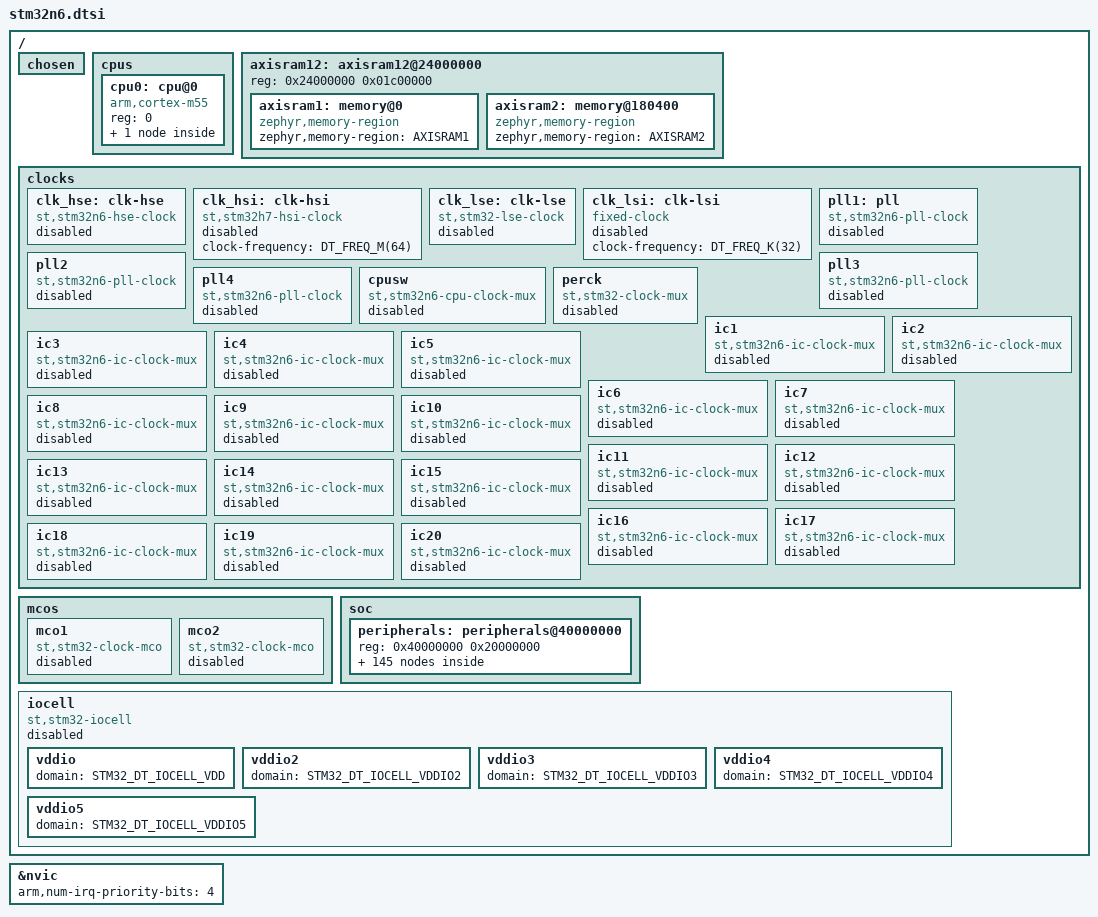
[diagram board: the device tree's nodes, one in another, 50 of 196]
/*
 * Copyright (c) 2024 STMicroelectronics
 * Copyright (c) 2025 Mario Paja
 *
 * SPDX-License-Identifier: Apache-2.0
 */

#include <arm/armv8.1-m.dtsi>
#include <zephyr/dt-bindings/adc/adc.h>
#include <zephyr/dt-bindings/clock/stm32n6_clock.h>
#include <zephyr/dt-bindings/dma/stm32_dma.h>
#include <zephyr/dt-bindings/i2c/i2c.h>
#include <zephyr/dt-bindings/reset/stm32n6_reset.h>
#include <zephyr/dt-bindings/memory-attr/memory-attr.h>
#include <zephyr/dt-bindings/memory-attr/memory-attr-arm.h>
#include <zephyr/dt-bindings/memory-controller/stm32-fmc-nor-psram.h>
#include <zephyr/dt-bindings/gpio/gpio.h>
#include <zephyr/dt-bindings/video/video-interfaces.h>
#include <zephyr/dt-bindings/power/stm32n6_iocell.h>
#include <freq.h>
#include <mem.h>

/ {
	chosen {
		zephyr,crc = &crc;
		zephyr,entropy = &rng;
	};

	cpus {
		#address-cells = <1>;
		#size-cells = <0>;

		cpu0: cpu@0 {
			device_type = "cpu";
			compatible = "arm,cortex-m55";
			reg = <0>;
			#address-cells = <1>;
			#size-cells = <1>;

			mpu: mpu@e000ed90 {
				compatible = "arm,armv8.1m-mpu";
				reg = <0xe000ed90 0x40>;
			};
		};
	};

	axisram12: axisram12@24000000 {
		#address-cells = <1>;
		#size-cells = <1>;
		/* This node described FLEXMEM, AXISRAM1 and AXISRAM2 */
		reg = <0x24000000 0x01c00000>;
		ranges = <0x0 0x34000000 DT_SIZE_M(2)>;

		axisram1: memory@0 {
			compatible = "zephyr,memory-region", "mmio-sram";
			zephyr,memory-region = "AXISRAM1";
		};

		axisram2: memory@180400 {
			compatible = "zephyr,memory-region", "mmio-sram";
			zephyr,memory-region = "AXISRAM2";
		};
	};

	clocks {
		clk_hse: clk-hse {
			#clock-cells = <0>;
			compatible = "st,stm32n6-hse-clock";
			status = "disabled";
		};

		clk_hsi: clk-hsi {
			#clock-cells = <0>;
			compatible = "st,stm32h7-hsi-clock";
			clock-frequency = <DT_FREQ_M(64)>;
			status = "disabled";
		};

		clk_lse: clk-lse {
			#clock-cells = <0>;
			compatible = "st,stm32-lse-clock";
			clock-frequency = <32768>;
			driving-capability = <2>;
			status = "disabled";
		};

		clk_lsi: clk-lsi {
			#clock-cells = <0>;
			compatible = "fixed-clock";
			clock-frequency = <DT_FREQ_K(32)>;
			status = "disabled";
		};

		pll1: pll: pll {
			#clock-cells = <0>;
			compatible = "st,stm32n6-pll-clock";
			status = "disabled";
		};

		pll2: pll2 {
			#clock-cells = <0>;
			compatible = "st,stm32n6-pll-clock";
			status = "disabled";
		};

		pll3: pll3 {
			#clock-cells = <0>;
			compatible = "st,stm32n6-pll-clock";
			status = "disabled";
		};

		pll4: pll4 {
			#clock-cells = <0>;
			compatible = "st,stm32n6-pll-clock";
			status = "disabled";
		};

		cpusw: cpusw {
			#clock-cells = <0>;
			compatible = "st,stm32n6-cpu-clock-mux", "st,stm32-clock-mux";
			status = "disabled";
		};

		perck: perck {
			#clock-cells = <0>;
			compatible = "st,stm32-clock-mux";
			status = "disabled";
		};

		ic1: ic1 {
			#clock-cells = <0>;
			compatible = "st,stm32n6-ic-clock-mux";
			status = "disabled";
		};

		ic2: ic2 {
			#clock-cells = <0>;
			compatible = "st,stm32n6-ic-clock-mux";
			status = "disabled";
		};

		ic3: ic3 {
			#clock-cells = <0>;
			compatible = "st,stm32n6-ic-clock-mux";
			status = "disabled";
		};

		ic4: ic4 {
			#clock-cells = <0>;
			compatible = "st,stm32n6-ic-clock-mux";
			status = "disabled";
		};

		ic5: ic5 {
			#clock-cells = <0>;
			compatible = "st,stm32n6-ic-clock-mux";
			status = "disabled";
		};

		ic6: ic6 {
			#clock-cells = <0>;
			compatible = "st,stm32n6-ic-clock-mux";
			status = "disabled";
		};

		ic7: ic7 {
			#clock-cells = <0>;
			compatible = "st,stm32n6-ic-clock-mux";
			status = "disabled";
		};

		ic8: ic8 {
			#clock-cells = <0>;
			compatible = "st,stm32n6-ic-clock-mux";
			status = "disabled";
		};

		ic9: ic9 {
			#clock-cells = <0>;
			compatible = "st,stm32n6-ic-clock-mux";
			status = "disabled";
		};

		ic10: ic10 {
			#clock-cells = <0>;
			compatible = "st,stm32n6-ic-clock-mux";
			status = "disabled";
		};

		ic11: ic11 {
			#clock-cells = <0>;
			compatible = "st,stm32n6-ic-clock-mux";
			status = "disabled";
		};

		ic12: ic12 {
			#clock-cells = <0>;
			compatible = "st,stm32n6-ic-clock-mux";
			status = "disabled";
		};

		ic13: ic13 {
			#clock-cells = <0>;
			compatible = "st,stm32n6-ic-clock-mux";
			status = "disabled";
		};

		ic14: ic14 {
			#clock-cells = <0>;
			compatible = "st,stm32n6-ic-clock-mux";
			status = "disabled";
		};

		ic15: ic15 {
			#clock-cells = <0>;
			compatible = "st,stm32n6-ic-clock-mux";
			status = "disabled";
		};

		ic16: ic16 {
			#clock-cells = <0>;
			compatible = "st,stm32n6-ic-clock-mux";
			status = "disabled";
		};

		ic17: ic17 {
			#clock-cells = <0>;
			compatible = "st,stm32n6-ic-clock-mux";
			status = "disabled";
		};

		ic18: ic18 {
			#clock-cells = <0>;
			compatible = "st,stm32n6-ic-clock-mux";
			status = "disabled";
		};

		ic19: ic19 {
			#clock-cells = <0>;
			compatible = "st,stm32n6-ic-clock-mux";
			status = "disabled";
		};

		ic20: ic20 {
			#clock-cells = <0>;
			compatible = "st,stm32n6-ic-clock-mux";
			status = "disabled";
		};
	};

	mcos {
		mco1: mco1 {
			#clock-cells = <2>;
			compatible = "st,stm32-clock-mco";
			clocks = <&rcc STM32_CLOCK(MISC, 1)>,
				 <&rcc STM32_SRC_HSI MCO1_SEL(MCO1_SEL_HSI)>;
			clock-names = "clken", "clksel";
			status = "disabled";
		};

		mco2: mco2 {
			#clock-cells = <2>;
			compatible = "st,stm32-clock-mco";
			clocks = <&rcc STM32_CLOCK(MISC, 2)>,
				 <&rcc STM32_SRC_HSI MCO2_SEL(MCO2_SEL_HSI)>;
			clock-names = "clken", "clksel";
			status = "disabled";
		};
	};

	soc {
		#address-cells = <1>;
		#size-cells = <1>;

		peripherals: peripherals@40000000 {
			#address-cells = <1>;
			#size-cells = <1>;
			reg = <0x40000000 0x20000000>;
			/* Default use the secure addresses range */
			ranges = <0x0 0x50000000 0x10000000>;

			rcc: rcc@6028000 {
				compatible = "st,stm32n6-rcc";
				clocks-controller;
				#clock-cells = <2>;
				reg = <0x6028000 0x2000>;

				rctl: reset-controller {
					compatible = "st,stm32-rcc-rctl";
					#reset-cells = <1>;
				};
			};

			ramcfg_sram3_axi: ramcfg@2023100 {
				compatible = "st,stm32n6-ramcfg";
				#address-cells = <1>;
				#size-cells = <1>;
				reg = <0x2023100 0x80>;
				clocks = <&rcc STM32_CLOCK(MEM, 0)>, <&rcc STM32_CLOCK(AHB2, 12)>;
				clock-names = "axisram", "ramcfg";
				ranges = <0x0 0x34200000 DT_SIZE_K(448)>;

				axisram3: memory@0 {
					compatible = "zephyr,memory-region", "mmio-sram";
					zephyr,memory-region = "AXISRAM3";
					zephyr,memory-attr = <DT_MEM_ARM(ATTR_MPU_RAM)>;
				};
			};

			ramcfg_sram4_axi: ramcfg@2023180 {
				compatible = "st,stm32n6-ramcfg";
				#address-cells = <1>;
				#size-cells = <1>;
				reg = <0x2023180 0x80>;
				clocks = <&rcc STM32_CLOCK(MEM, 1)>, <&rcc STM32_CLOCK(AHB2, 12)>;
				clock-names = "axisram", "ramcfg";
				ranges = <0x0 0x34270000 DT_SIZE_K(448)>;

				axisram4: memory@0 {
					compatible = "zephyr,memory-region", "mmio-sram";
					zephyr,memory-region = "AXISRAM4";
					zephyr,memory-attr = <DT_MEM_ARM(ATTR_MPU_RAM)>;
				};
			};

			ramcfg_sram5_axi: ramcfg@2023200 {
				compatible = "st,stm32n6-ramcfg";
				#address-cells = <1>;
				#size-cells = <1>;
				reg = <0x2023200 0x80>;
				clocks = <&rcc STM32_CLOCK(MEM, 2)>, <&rcc STM32_CLOCK(AHB2, 12)>;
				clock-names = "axisram", "ramcfg";
				ranges = <0x0 0x342e0000 DT_SIZE_K(448)>;

				axisram5: memory@0 {
					compatible = "zephyr,memory-region", "mmio-sram";
					zephyr,memory-region = "AXISRAM5";
					zephyr,memory-attr = <DT_MEM_ARM(ATTR_MPU_RAM)>;
				};
			};

			ramcfg_sram6_axi: ramcfg@2023280 {
				compatible = "st,stm32n6-ramcfg";
				#address-cells = <1>;
				#size-cells = <1>;
				reg = <0x2023280 0x80>;
				clocks = <&rcc STM32_CLOCK(MEM, 3)>, <&rcc STM32_CLOCK(AHB2, 12)>;
				clock-names = "axisram", "ramcfg";
				ranges = <0x0 0x34350000 DT_SIZE_K(448)>;

				axisram6: memory@0 {
					compatible = "zephyr,memory-region", "mmio-sram";
					zephyr,memory-region = "AXISRAM6";
					zephyr,memory-attr = <DT_MEM_ARM(ATTR_MPU_RAM)>;
				};
			};

			exti: interrupt-controller@6025000 {
				compatible = "st,stm32g0-exti", "st,stm32-exti";
				interrupt-controller;
				#interrupt-cells = <1>;
				#address-cells = <0>;
				reg = <0x6025000 0x400>;
				clocks = <&rcc STM32_CLOCK(APB4_2, 0)>;
				num-lines = <96>;
				interrupts = <20 0>, <21 0>, <22 0>, <23 0>,
					     <24 0>, <25 0>, <26 0>, <27 0>,
					     <28 0>, <29 0>, <30 0>, <31 0>,
					     <32 0>, <33 0>, <34 0>, <35 0>;
				interrupt-names = "line0", "line1", "line2", "line3",
						  "line4", "line5", "line6", "line7",
						  "line8", "line9", "line10", "line11",
						  "line12", "line13", "line14", "line15";
				line-ranges = <0 1>, <1 1>, <2 1>, <3 1>,
					      <4 1>, <5 1>, <6 1>, <7 1>,
					      <8 1>, <9 1>, <10 1>, <11 1>,
					      <12 1>, <13 1>, <14 1>, <15 1>;
			};

			pinctrl: pin-controller@6020000 {
				compatible = "st,stm32n6-pinctrl", "st,stm32-pinctrl";
				#address-cells = <1>;
				#size-cells = <1>;
				reg = <0x6020000 0x2000>;
				ranges;

				gpioa: gpio@6020000 {
					compatible = "st,stm32-gpio";
					gpio-controller;
					#gpio-cells = <2>;
					reg = <0x6020000 0x400>;
					clocks = <&rcc STM32_CLOCK(AHB4, 0)>;
				};

				gpiob: gpio@6020400 {
					compatible = "st,stm32-gpio";
					gpio-controller;
					#gpio-cells = <2>;
					reg = <0x6020400 0x400>;
					clocks = <&rcc STM32_CLOCK(AHB4, 1)>;
				};

				gpioc: gpio@6020800 {
					compatible = "st,stm32-gpio";
					gpio-controller;
					#gpio-cells = <2>;
					reg = <0x6020800 0x400>;
					clocks = <&rcc STM32_CLOCK(AHB4, 2)>;
				};

				gpiod: gpio@6020c00 {
					compatible = "st,stm32-gpio";
					gpio-controller;
					#gpio-cells = <2>;
					reg = <0x6020c00 0x400>;
					clocks = <&rcc STM32_CLOCK(AHB4, 3)>;
				};

				gpioe: gpio@6021000 {
					compatible = "st,stm32-gpio";
					gpio-controller;
					#gpio-cells = <2>;
					reg = <0x6021000 0x400>;
					clocks = <&rcc STM32_CLOCK(AHB4, 4)>;
				};

				gpiof: gpio@6021400 {
					compatible = "st,stm32-gpio";
					gpio-controller;
					#gpio-cells = <2>;
					reg = <0x6021400 0x400>;
					clocks = <&rcc STM32_CLOCK(AHB4, 5)>;
				};

				gpiog: gpio@6021800 {
					compatible = "st,stm32-gpio";
					gpio-controller;
					#gpio-cells = <2>;
					reg = <0x6021800 0x400>;
					clocks = <&rcc STM32_CLOCK(AHB4, 6)>;
				};

				gpioh: gpio@6021c00 {
					compatible = "st,stm32-gpio";
					gpio-controller;
					#gpio-cells = <2>;
					reg = <0x6021c00 0x400>;
					clocks = <&rcc STM32_CLOCK(AHB4, 7)>;
				};

				gpion: gpio@6023400 {
					compatible = "st,stm32-gpio";
					gpio-controller;
					#gpio-cells = <2>;
					reg = <0x6023400 0x400>;
					clocks = <&rcc STM32_CLOCK(AHB4, 13)>;
				};

				gpioo: gpio@6023800 {
					compatible = "st,stm32-gpio";
					gpio-controller;
					#gpio-cells = <2>;
					reg = <0x6023800 0x400>;
					clocks = <&rcc STM32_CLOCK(AHB4, 14)>;
				};

				gpiop: gpio@6023c00 {
					compatible = "st,stm32-gpio";
					gpio-controller;
					#gpio-cells = <2>;
					reg = <0x6023c00 0x400>;
					clocks = <&rcc STM32_CLOCK(AHB4, 15)>;
				};

				gpioq: gpio@6024000 {
					compatible = "st,stm32-gpio";
					gpio-controller;
					#gpio-cells = <2>;
					reg = <0x6024000 0x400>;
					clocks = <&rcc STM32_CLOCK(AHB4, 16)>;
				};
			};

			adc1: adc@22000 {
				compatible = "st,stm32n6-adc", "st,stm32-adc";
				reg = <0x22000 0x400>;
				clocks = <&rcc STM32_CLOCK(AHB1, 5)>;
				clock-names = "adcx";
				interrupts = <46 0>;
				#io-channel-cells = <1>;
				st,adc-resolutions = <12 10 8 6>;
				sampling-times = <2 3 7 12 14 47 247 1500>;
				st,adc-sequencer = "programmable";
				st,adc-oversampler = "extended";
				st,adc-internal-regulator = "none";
				st,adc-has-deep-powerdown;
				st,adc-has-channel-preselection;
				status = "disabled";
			};

			adc2: adc@22100 {
				compatible = "st,stm32n6-adc", "st,stm32-adc";
				reg = <0x22100 0x300>;
				clocks = <&rcc STM32_CLOCK(AHB1, 5)>;
				clock-names = "adcx";
				interrupts = <46 0>;
				#io-channel-cells = <1>;
				st,adc-resolutions = <12 10 8 6>;
				sampling-times = <2 3 7 12 14 47 247 1500>;
				st,adc-sequencer = "programmable";
				st,adc-oversampler = "extended";
				st,adc-internal-regulator = "none";
				st,adc-has-deep-powerdown;
				st,adc-has-channel-preselection;
				status = "disabled";
			};

			fdcan1: can@a000 {
				compatible = "st,stm32h7-fdcan";
				reg = <0xa000 0x400>, <0xc000 0xd54>;
				reg-names = "m_can", "message_ram";
				clocks = <&rcc STM32_CLOCK(APB1_2, 8)>;
				interrupts = <180 0>, <181 0>, <186 0>;
				interrupt-names = "int0", "int1", "calib";
				bosch,mram-cfg = <0x0 28 8 3 3 0 3 3>;
				status = "disabled";
			};

			fdcan2: can@a400 {
				compatible = "st,stm32h7-fdcan";
				reg = <0xa400 0x400>, <0xc000 0x1aa8>;
				reg-names = "m_can", "message_ram";
				clocks = <&rcc STM32_CLOCK(APB1_2, 8)>;
				interrupts = <182 0>, <183 0>;
				interrupt-names = "int0", "int1";
				bosch,mram-cfg = <0xd54 28 8 3 3 0 3 3>;
				status = "disabled";
			};

			fdcan3: can@e800 {
				compatible = "st,stm32h7-fdcan";
				reg = <0xe800 0x400>, <0xc000 0x2800>;
				reg-names = "m_can", "message_ram";
				clocks = <&rcc STM32_CLOCK(APB1_2, 8)>;
				interrupts = <184 0>, <185 0>;
				interrupt-names = "int0", "int1";
				bosch,mram-cfg = <0x1aa8 28 8 3 3 0 3 3>;
				status = "disabled";
			};

			usart1: serial@2001000 {
				compatible = "st,stm32-usart", "st,stm32-uart";
				reg = <0x2001000 0x400>;
				clocks = <&rcc STM32_CLOCK(APB2, 4)>;
				resets = <&rctl STM32_RESET(APB2, 4)>;
				interrupts = <159 0>;
				status = "disabled";
			};

			usart2: serial@4400 {
				compatible = "st,stm32-usart", "st,stm32-uart";
				reg = <0x4400 0x400>;
				clocks = <&rcc STM32_CLOCK(APB1, 17)>;
				resets = <&rctl STM32_RESET(APB1L, 17)>;
				interrupts = <160 0>;
				status = "disabled";
			};

			usart3: serial@4800 {
				compatible = "st,stm32-usart", "st,stm32-uart";
				reg = <0x4800 0x400>;
				clocks = <&rcc STM32_CLOCK(APB1, 18)>;
				resets = <&rctl STM32_RESET(APB1L, 18)>;
				interrupts = <161 0>;
				status = "disabled";
			};

			uart4: serial@4c00 {
				compatible = "st,stm32-usart", "st,stm32-uart";
				reg = <0x4c00 0x400>;
				clocks = <&rcc STM32_CLOCK(APB1, 19)>;
				resets = <&rctl STM32_RESET(APB1L, 19)>;
				interrupts = <162 0>;
				status = "disabled";
			};

			uart5: serial@5000 {
				compatible = "st,stm32-usart", "st,stm32-uart";
				reg = <0x5000 0x400>;
				clocks = <&rcc STM32_CLOCK(APB1, 20)>;
				resets = <&rctl STM32_RESET(APB1L, 20)>;
				interrupts = <163 0>;
				status = "disabled";
			};

			usart6: serial@2001400 {
				compatible = "st,stm32-usart", "st,stm32-uart";
				reg = <0x2001400 0x400>;
				clocks = <&rcc STM32_CLOCK(APB2, 5)>;
				resets = <&rctl STM32_RESET(APB2, 5)>;
				interrupts = <164 0>;
				status = "disabled";
			};

			uart7: serial@7800 {
				compatible = "st,stm32-usart", "st,stm32-uart";
				reg = <0x7800 0x400>;
				clocks = <&rcc STM32_CLOCK(APB1, 30)>;
				resets = <&rctl STM32_RESET(APB1L, 30)>;
				interrupts = <165 0>;
				status = "disabled";
			};

			uart8: serial@7c00 {
				compatible = "st,stm32-usart", "st,stm32-uart";
				reg = <0x7c00 0x400>;
				clocks = <&rcc STM32_CLOCK(APB1, 31)>;
				resets = <&rctl STM32_RESET(APB1L, 31)>;
				interrupts = <166 0>;
				status = "disabled";
			};

			uart9: serial@2001800 {
				compatible = "st,stm32-usart", "st,stm32-uart";
				reg = <0x2001800 0x400>;
				clocks = <&rcc STM32_CLOCK(APB2, 6)>;
				resets = <&rctl STM32_RESET(APB2, 6)>;
				interrupts = <167 0>;
				status = "disabled";
			};

			usart10: serial@2001c00 {
				compatible = "st,stm32-usart", "st,stm32-uart";
				reg = <0x2001c00 0x400>;
				clocks = <&rcc STM32_CLOCK(APB2, 7)>;
				resets = <&rctl STM32_RESET(APB2, 7)>;
				interrupts = <168 0>;
				status = "disabled";
			};

			i2c1: i2c@5400 {
				compatible = "st,stm32-i2c-v2";
				clock-frequency = <I2C_BITRATE_STANDARD>;
				#address-cells = <1>;
				#size-cells = <0>;
				reg = <0x5400 0x400>;
				clocks = <&rcc STM32_CLOCK(APB1, 21)>;
				interrupts = <100 0>, <101 0>;
				interrupt-names = "event", "error";
				status = "disabled";
			};

			i2c2: i2c@5800 {
				compatible = "st,stm32-i2c-v2";
				clock-frequency = <I2C_BITRATE_STANDARD>;
				#address-cells = <1>;
				#size-cells = <0>;
				reg = <0x5800 0x400>;
				clocks = <&rcc STM32_CLOCK(APB1, 22)>;
				interrupts = <102 0>, <103 0>;
				interrupt-names = "event", "error";
				status = "disabled";
			};

			i2c3: i2c@5c00 {
				compatible = "st,stm32-i2c-v2";
				clock-frequency = <I2C_BITRATE_STANDARD>;
				#address-cells = <1>;
				#size-cells = <0>;
				reg = <0x5c00 0x400>;
				clocks = <&rcc STM32_CLOCK(APB1, 23)>;
				interrupts = <104 0>, <105 0>;
				interrupt-names = "event", "error";
				status = "disabled";
			};

			i2c4: i2c@6001c00 {
				compatible = "st,stm32-i2c-v2";
				clock-frequency = <I2C_BITRATE_STANDARD>;
				#address-cells = <1>;
				#size-cells = <0>;
				reg = <0x6001c00 0x400>;
				clocks = <&rcc STM32_CLOCK(APB4, 7)>;
				interrupts = <106 0>, <107 0>;
				interrupt-names = "event", "error";
				status = "disabled";
			};

			i2s1: i2s@2003000 {
				compatible = "st,stm32h7-i2s", "st,stm32-i2s";
				#address-cells = <1>;
				#size-cells = <0>;
				reg = <0x2003000 0x400>;
				interrupts = <153 0>;
				clocks = <&rcc STM32_CLOCK(APB2, 12)>;
				dmas = <&gpdma1 0 80 (STM32_DMA_PERIPH_TX |
						      STM32_DMA_PRIORITY_HIGH)>,
				       <&gpdma1 1 79 (STM32_DMA_PERIPH_RX |
						      STM32_DMA_PRIORITY_HIGH)>;
				dma-names = "tx", "rx";
				status = "disabled";
			};

			i2s2: i2s@3800 {
				compatible = "st,stm32h7-i2s", "st,stm32-i2s";
				#address-cells = <1>;
				#size-cells = <0>;
				reg = <0x3800 0x400>;
				interrupts = <154 0>;
				clocks = <&rcc STM32_CLOCK(APB1, 14)>;
				dmas = <&gpdma1 0 82 (STM32_DMA_PERIPH_TX |
						      STM32_DMA_PRIORITY_HIGH)>,
				       <&gpdma1 1 81 (STM32_DMA_PERIPH_RX |
						      STM32_DMA_PRIORITY_HIGH)>;
				dma-names = "tx", "rx";
				status = "disabled";
			};

			i2s3: i2s@3c00 {
				compatible = "st,stm32h7-i2s", "st,stm32-i2s";
				#address-cells = <1>;
				#size-cells = <0>;
				reg = <0x3c00 0x400>;
				interrupts = <155 0>;
				clocks = <&rcc STM32_CLOCK(APB1, 15)>;
				dmas = <&gpdma1 0 84 (STM32_DMA_PERIPH_TX |
						      STM32_DMA_PRIORITY_HIGH)>,
				       <&gpdma1 1 83 (STM32_DMA_PERIPH_RX |
						      STM32_DMA_PRIORITY_HIGH)>;
				dma-names = "tx", "rx";
				status = "disabled";
			};

			i2s6: i2s@6001400 {
				compatible = "st,stm32h7-i2s", "st,stm32-i2s";
				#address-cells = <1>;
				#size-cells = <0>;
				reg = <0x6001400 0x400>;
				interrupts = <158 0>;
				clocks = <&rcc STM32_CLOCK(APB4, 5)>;
				dmas = <&gpdma1 0 90 (STM32_DMA_PERIPH_TX |
						      STM32_DMA_PRIORITY_HIGH)>,
				       <&gpdma1 1 89 (STM32_DMA_PERIPH_RX |
						      STM32_DMA_PRIORITY_HIGH)>;
				dma-names = "tx", "rx";
				status = "disabled";
			};

			i3c1: i3c@6000 {
				compatible = "st,stm32-i3c";
				reg = <0x6000 0x400>;
				interrupts = <108 0>, <109 0>;
				interrupt-names = "event", "error";
				#address-cells = <3>;
				#size-cells = <0>;
				clocks = <&rcc STM32_CLOCK(APB1, 24)>;
				resets = <&rctl STM32_RESET(APB1L, 24)>;
				zephyr,pm-device-runtime-auto;
				status = "disabled";
			};

			i3c2: i3c@6400 {
				compatible = "st,stm32-i3c";
				reg = <0x6400 0x400>;
				interrupts = <110 0>, <111 0>;
				interrupt-names = "event", "error";
				#address-cells = <3>;
				#size-cells = <0>;
				clocks = <&rcc STM32_CLOCK(APB1, 25)>;
				resets = <&rctl STM32_RESET(APB1L, 25)>;
				zephyr,pm-device-runtime-auto;
				status = "disabled";
			};

			spi1: spi@2003000 {
				compatible = "st,stm32h7-spi", "st,stm32-spi-fifo", "st,stm32-spi";
				#address-cells = <1>;
				#size-cells = <0>;
				reg = <0x2003000 0x400>;
				interrupts = <153 0>;
				clocks = <&rcc STM32_CLOCK(APB2, 12)>;
				st,spi-data-width = "full-4-to-32-bit";
				fifo-size = <16>;
				fifo-max-transfer-size = <65535>;
				status = "disabled";
			};

			spi2: spi@3800 {
				compatible = "st,stm32h7-spi", "st,stm32-spi-fifo", "st,stm32-spi";
				#address-cells = <1>;
				#size-cells = <0>;
				reg = <0x3800 0x400>;
				interrupts = <154 0>;
				clocks = <&rcc STM32_CLOCK(APB1, 14)>;
				st,spi-data-width = "full-4-to-32-bit";
				fifo-size = <16>;
				fifo-max-transfer-size = <65535>;
				status = "disabled";
			};

			spi3: spi@3c00 {
				compatible = "st,stm32h7-spi", "st,stm32-spi-fifo", "st,stm32-spi";
				#address-cells = <1>;
				#size-cells = <0>;
				reg = <0x3c00 0x400>;
				interrupts = <155 0>;
				clocks = <&rcc STM32_CLOCK(APB1, 15)>;
				st,spi-data-width = "full-4-to-32-bit";
				fifo-size = <16>;
				fifo-max-transfer-size = <65535>;
				status = "disabled";
			};

			spi4: spi@2003400 {
				compatible = "st,stm32h7-spi", "st,stm32-spi-fifo", "st,stm32-spi";
				#address-cells = <1>;
				#size-cells = <0>;
				reg = <0x2003400 0x400>;
				interrupts = <156 0>;
				clocks = <&rcc STM32_CLOCK(APB2, 13)>;
				st,spi-data-width = "full-4-to-16-bit";
				fifo-size = <8>;
				fifo-max-transfer-size = <65535>;
				status = "disabled";
			};

			spi5: spi@2005000 {
				compatible = "st,stm32h7-spi", "st,stm32-spi-fifo", "st,stm32-spi";
				#address-cells = <1>;
				#size-cells = <0>;
				reg = <0x2005000 0x400>;
				interrupts = <157 0>;
				clocks = <&rcc STM32_CLOCK(APB2, 20)>;
				st,spi-data-width = "full-4-to-16-bit";
				fifo-size = <8>;
				fifo-max-transfer-size = <65535>;
				status = "disabled";
			};

			spi6: spi@6001400 {
				compatible = "st,stm32h7-spi", "st,stm32-spi-fifo", "st,stm32-spi";
				#address-cells = <1>;
				#size-cells = <0>;
				reg = <0x6001400 0x400>;
				interrupts = <158 0>;
				clocks = <&rcc STM32_CLOCK(APB4, 5)>;
				st,spi-data-width = "full-4-to-32-bit";
				fifo-size = <16>;
				fifo-max-transfer-size = <65535>;
				status = "disabled";
			};

			gpdma1: dma@21000 {
				compatible = "st,stm32u5-dma";
				#dma-cells = <3>;
				reg = <0x21000 0x1000>;
				clocks = <&rcc STM32_CLOCK(AHB1, 4)>;
				interrupts = <84 0 85 0 86 0 87 0 88 0 89 0 90 0 91 0
					      92 0 93 0 94 0 95 0 96 0 97 0 98 0 99 0>;
				dma-channels = <16>;
				dma-requests = <144>;
				dma-offset = <0>;
				status = "disabled";
			};

			bsec: efuse@6009000 {
				compatible = "st,stm32-bsec";
				reg = <0x6009000 0x1000>;
				st,upper-fuse-limit = <256>;
				status = "disabled";

				nvmem-layout {
					compatible = "fixed-layout";
					#address-cells = <1>;
					#size-cells = <1>;

					otp124_hconf1: opt124_hconf1@1f0 {
						reg = <0x1f0 0x4>;
						#nvmem-cell-cells = <0>;
					};

					mac_address0: mac-address@2a4 {
						reg = <0x2a4 0x6>;
						#nvmem-cell-cells = <0>;
					};

					mac_address1: mac-address@2ac {
						reg = <0x2ac 0x6>;
						#nvmem-cell-cells = <0>;
					};
				};
			};

			dcmipp: dcmipp@8002000 {
				compatible = "st,stm32-dcmipp";
				reg = <0x8002000 0x1000>;
				clock-names = "dcmipp", "dcmipp-ker", "csi";
				clocks = <&rcc STM32_CLOCK(APB5, 2)>,
					 <&rcc STM32_SRC_IC17 DCMIPP_SEL(2)>,
					 <&rcc STM32_CLOCK(APB5, 6)>;
				interrupts = <48 0>, <47 0>;
				interrupt-names = "dcmipp", "dcmipp_csi";
				resets = <&rctl STM32_RESET(APB5, 2)>,
					 <&rctl STM32_RESET(APB5, 6)>;
				status = "disabled";

				pipes {
					compatible = "st,stm32-dcmipp-pipes";
					#address-cells = <1>;
					#size-cells = <0>;

					pipe_dump: pipe@0 {
						reg = <0>;
					};

					pipe_main: pipe@1 {
						reg = <1>;
					};

					pipe_aux: pipe@2 {
						reg = <2>;
					};
				};

				port {
					endpoint {
						remote-endpoint-label = "";
						bus-type = <VIDEO_BUS_TYPE_CSI2_DPHY>;
					};
				};
			};

			ethernet@8036000 {
				reg = <0x8036000 0x8000>;
				compatible = "st,stm32-ethernet-controller";
				clock-names = "stm-eth", "mac-clk-tx", "mac-clk-rx";
				clocks = <&rcc STM32_CLOCK(AHB5, 22)>,
					 <&rcc STM32_CLOCK(AHB5, 23)>,
					 <&rcc STM32_CLOCK(AHB5, 24)>;

				mac: ethernet {
					compatible = "st,stm32n6-ethernet", "st,stm32h7-ethernet",
						     "st,stm32-ethernet";
					interrupts = <179 0>;
					status = "disabled";
				};

				mdio: mdio {
					compatible = "st,stm32-mdio";
					#address-cells = <1>;
					#size-cells = <0>;
					status = "disabled";
				};
			};

			sdmmc1: sdmmc@8027000 {
				compatible = "st,stm32-sdmmc";
				reg = <0x8027000 0x1000>;
				clocks = <&rcc STM32_CLOCK(AHB5, 8)>;
				resets = <&rctl STM32_RESET(AHB5, 8)>;
				interrupts = <174 0>;
				status = "disabled";
			};

			sdmmc2: sdmmc@8026800 {
				compatible = "st,stm32-sdmmc";
				reg = <0x8026800 0x400>;
				clocks = <&rcc STM32_CLOCK(AHB5, 7)>;
				resets = <&rctl STM32_RESET(AHB5, 7)>;
				interrupts = <175 0>;
				status = "disabled";
			};

			timers1: timers@2000000 {
				compatible = "st,stm32-timers";
				reg = <0x2000000 0x400>;
				clocks = <&rcc STM32_CLOCK(APB2, 0)>,
					 <&rcc STM32_SRC_TIMG NO_SEL>;
				resets = <&rctl STM32_RESET(APB2, 0)>;
				interrupts = <112 0>, <113 0>, <114 0>, <115 0>;
				interrupt-names = "brk", "up", "trgcom", "cc";
				status = "disabled";

				pwm {
					compatible = "st,stm32-pwm";
					status = "disabled";
					#pwm-cells = <3>;
				};

				counter {
					compatible = "st,stm32-counter";
					status = "disabled";
				};
			};

			timers2: timers@0 {
				compatible = "st,stm32-timers";
				reg = <0x0 0x400>;
				clocks = <&rcc STM32_CLOCK(APB1, 0)>,
					 <&rcc STM32_SRC_TIMG NO_SEL>;
				resets = <&rctl STM32_RESET(APB1L, 0)>;
				interrupts = <116 0>;
				interrupt-names = "global";
				status = "disabled";

				pwm {
					compatible = "st,stm32-pwm";
					status = "disabled";
					#pwm-cells = <3>;
				};

				counter {
					compatible = "st,stm32-counter";
					status = "disabled";
				};
			};

			timers3: timers@400 {
				compatible = "st,stm32-timers";
				reg = <0x400 0x400>;
				clocks = <&rcc STM32_CLOCK(APB1, 1)>,
					 <&rcc STM32_SRC_TIMG NO_SEL>;
				resets = <&rctl STM32_RESET(APB1L, 1)>;
				interrupts = <117 0>;
				interrupt-names = "global";
				status = "disabled";

				pwm {
					compatible = "st,stm32-pwm";
					status = "disabled";
					#pwm-cells = <3>;
				};

				counter {
					compatible = "st,stm32-counter";
					status = "disabled";
				};
			};

			timers4: timers@800 {
				compatible = "st,stm32-timers";
				reg = <0x800 0x400>;
				clocks = <&rcc STM32_CLOCK(APB1, 2)>,
					 <&rcc STM32_SRC_TIMG NO_SEL>;
				resets = <&rctl STM32_RESET(APB1L, 2)>;
				interrupts = <118 0>;
				interrupt-names = "global";
				status = "disabled";

				pwm {
					compatible = "st,stm32-pwm";
					status = "disabled";
					#pwm-cells = <3>;
				};

				counter {
					compatible = "st,stm32-counter";
					status = "disabled";
				};
			};

			timers5: timers@c00 {
				compatible = "st,stm32-timers";
				reg = <0xc00 0x400>;
				clocks = <&rcc STM32_CLOCK(APB1, 3)>,
					 <&rcc STM32_SRC_TIMG NO_SEL>;
				resets = <&rctl STM32_RESET(APB1L, 3)>;
				interrupts = <119 0>;
				interrupt-names = "global";
				status = "disabled";

				pwm {
					compatible = "st,stm32-pwm";
					status = "disabled";
					#pwm-cells = <3>;
				};

				counter {
					compatible = "st,stm32-counter";
					status = "disabled";
				};
			};

			timers6: timers@1000 {
				compatible = "st,stm32-timers";
				reg = <0x1000 0x400>;
				clocks = <&rcc STM32_CLOCK(APB1, 4)>,
					 <&rcc STM32_SRC_TIMG NO_SEL>;
				resets = <&rctl STM32_RESET(APB1L, 4)>;
				interrupts = <120 0>;
				interrupt-names = "global";
				status = "disabled";

				counter {
					compatible = "st,stm32-counter";
					status = "disabled";
				};
			};

			timers7: timers@1400 {
				compatible = "st,stm32-timers";
				reg = <0x1400 0x400>;
				clocks = <&rcc STM32_CLOCK(APB1, 5)>,
					 <&rcc STM32_SRC_TIMG NO_SEL>;
				resets = <&rctl STM32_RESET(APB1L, 5)>;
				interrupts = <121 0>;
				interrupt-names = "global";
				status = "disabled";

				counter {
					compatible = "st,stm32-counter";
					status = "disabled";
				};
			};

			timers8: timers@2000400 {
				compatible = "st,stm32-timers";
				reg = <0x2000400 0x400>;
				clocks = <&rcc STM32_CLOCK(APB2, 1)>,
					 <&rcc STM32_SRC_TIMG NO_SEL>;
				resets = <&rctl STM32_RESET(APB2, 1)>;
				interrupts = <122 0>, <123 0>, <124 0>, <125 0>;
				interrupt-names = "brk", "up", "trgcom", "cc";
				status = "disabled";

				pwm {
					compatible = "st,stm32-pwm";
					status = "disabled";
					#pwm-cells = <3>;
				};

				counter {
					compatible = "st,stm32-counter";
					status = "disabled";
				};
			};

			timers9: timers@2004c00 {
				compatible = "st,stm32-timers";
				reg = <0x2004c00 0x400>;
				clocks = <&rcc STM32_CLOCK(APB2, 19)>,
					 <&rcc STM32_SRC_TIMG NO_SEL>;
				resets = <&rctl STM32_RESET(APB2, 19)>;
				interrupts = <126 0>;
				interrupt-names = "global";
				status = "disabled";

				pwm {
					compatible = "st,stm32-pwm";
					status = "disabled";
					#pwm-cells = <3>;
				};

				counter {
					compatible = "st,stm32-counter";
					status = "disabled";
				};
			};

			timers10: timers@3000 {
				compatible = "st,stm32-timers";
				reg = <0x3000 0x400>;
				clocks = <&rcc STM32_CLOCK(APB1, 12)>,
					 <&rcc STM32_SRC_TIMG NO_SEL>;
				resets = <&rctl STM32_RESET(APB1L, 12)>;
				interrupts = <127 0>;
				interrupt-names = "global";
				status = "disabled";

				pwm {
					compatible = "st,stm32-pwm";
					status = "disabled";
					#pwm-cells = <3>;
				};

				counter {
					compatible = "st,stm32-counter";
					status = "disabled";
				};
			};

			timers11: timers@3400 {
				compatible = "st,stm32-timers";
				reg = <0x3400 0x400>;
				clocks = <&rcc STM32_CLOCK(APB1, 13)>,
					 <&rcc STM32_SRC_TIMG NO_SEL>;
				resets = <&rctl STM32_RESET(APB1L, 13)>;
				interrupts = <128 0>;
				interrupt-names = "global";
				status = "disabled";

				pwm {
					compatible = "st,stm32-pwm";
					status = "disabled";
					#pwm-cells = <3>;
				};

				counter {
					compatible = "st,stm32-counter";
					status = "disabled";
				};
			};

			timers12: timers@1800 {
				compatible = "st,stm32-timers";
				reg = <0x1800 0x400>;
				clocks = <&rcc STM32_CLOCK(APB1, 6)>,
					 <&rcc STM32_SRC_TIMG NO_SEL>;
				resets = <&rctl STM32_RESET(APB1L, 6)>;
				interrupts = <129 0>;
				interrupt-names = "global";
				status = "disabled";

				pwm {
					compatible = "st,stm32-pwm";
					status = "disabled";
					#pwm-cells = <3>;
				};

				counter {
					compatible = "st,stm32-counter";
					status = "disabled";
				};
			};

			timers13: timers@1c00 {
				compatible = "st,stm32-timers";
				reg = <0x1c00 0x400>;
				clocks = <&rcc STM32_CLOCK(APB1, 7)>,
					 <&rcc STM32_SRC_TIMG NO_SEL>;
				resets = <&rctl STM32_RESET(APB1L, 7)>;
				interrupts = <130 0>;
				interrupt-names = "global";
				status = "disabled";

				pwm {
					compatible = "st,stm32-pwm";
					status = "disabled";
					#pwm-cells = <3>;
				};

				counter {
					compatible = "st,stm32-counter";
					status = "disabled";
				};
			};

			timers14: timers@2000 {
				compatible = "st,stm32-timers";
				reg = <0x2000 0x400>;
				clocks = <&rcc STM32_CLOCK(APB1, 8)>,
					 <&rcc STM32_SRC_TIMG NO_SEL>;
				resets = <&rctl STM32_RESET(APB1L, 8)>;
				interrupts = <131 0>;
				interrupt-names = "global";
				status = "disabled";

				pwm {
					compatible = "st,stm32-pwm";
					status = "disabled";
					#pwm-cells = <3>;
				};

				counter {
					compatible = "st,stm32-counter";
					status = "disabled";
				};
			};

			timers15: timers@2004000 {
				compatible = "st,stm32-timers";
				reg = <0x2004000 0x400>;
				clocks = <&rcc STM32_CLOCK(APB2, 16)>,
					 <&rcc STM32_SRC_TIMG NO_SEL>;
				resets = <&rctl STM32_RESET(APB2, 16)>;
				interrupts = <132 0>;
				interrupt-names = "global";
				status = "disabled";

				pwm {
					compatible = "st,stm32-pwm";
					status = "disabled";
					#pwm-cells = <3>;
				};

				counter {
					compatible = "st,stm32-counter";
					status = "disabled";
				};
			};

			timers16: timers@2004400 {
				compatible = "st,stm32-timers";
				reg = <0x2004400 0x400>;
				clocks = <&rcc STM32_CLOCK(APB2, 17)>,
					 <&rcc STM32_SRC_TIMG NO_SEL>;
				resets = <&rctl STM32_RESET(APB2, 17)>;
				interrupts = <133 0>;
				interrupt-names = "global";
				status = "disabled";

				pwm {
					compatible = "st,stm32-pwm";
					status = "disabled";
					#pwm-cells = <3>;
				};

				counter {
					compatible = "st,stm32-counter";
					status = "disabled";
				};
			};

			timers17: timers@2004800 {
				compatible = "st,stm32-timers";
				reg = <0x2004800 0x400>;
				clocks = <&rcc STM32_CLOCK(APB2, 18)>,
					 <&rcc STM32_SRC_TIMG NO_SEL>;
				resets = <&rctl STM32_RESET(APB2, 18)>;
				interrupts = <134 0>;
				interrupt-names = "global";
				status = "disabled";

				pwm {
					compatible = "st,stm32-pwm";
					status = "disabled";
					#pwm-cells = <3>;
				};

				counter {
					compatible = "st,stm32-counter";
					status = "disabled";
				};
			};

			timers18: timers@2003c00 {
				compatible = "st,stm32-timers";
				reg = <0x2003c00 0x400>;
				clocks = <&rcc STM32_CLOCK(APB2, 15)>,
					 <&rcc STM32_SRC_TIMG NO_SEL>;
				resets = <&rctl STM32_RESET(APB2, 15)>;
				interrupts = <135 0>;
				interrupt-names = "global";
				status = "disabled";

				counter {
					compatible = "st,stm32-counter";
					status = "disabled";
				};
			};

			xspim: xspim@802b400 {
				compatible = "st,stm32-xspim";
				reg = <0x802b400 0x400>;
				clocks = <&rcc STM32_CLOCK(AHB5, 13)>;
				io-port-1 = <&xspi1>;
				io-port-2 = <&xspi2>;
				status = "disabled";
			};

			xspi1: xspi@8025000 {
				compatible = "st,stm32-xspi";
				reg = <0x8025000 0x1000>, <0x90000000 DT_SIZE_M(256)>;
				interrupts = <170 0>;
				clock-names = "xspix", "xspi-ker";
				clocks = <&rcc STM32_CLOCK(AHB5, 5)>,
					 <&rcc STM32_SRC_HCLK5 XSPI1_SEL(0)>;
				#address-cells = <1>;
				#size-cells = <0>;
				status = "disabled";
			};

			xspi2: spi@802a000 {
				compatible = "st,stm32-xspi";
				reg = <0x802a000 0x1000>, <0x70000000 DT_SIZE_M(256)>;
				interrupts = <171 0>;
				clock-names = "xspix", "xspi-ker";
				clocks = <&rcc STM32_CLOCK(AHB5, 12)>,
					 <&rcc STM32_SRC_HCLK5 XSPI2_SEL(0)>;
				#address-cells = <1>;
				#size-cells = <0>;
				status = "disabled";
			};

			xspi3: spi@802d000 {
				compatible = "st,stm32-xspi";
				reg = <0x802d000 0x1000>, <0x80000000 DT_SIZE_M(256)>;
				interrupts = <172 0>;
				clock-names = "xspix", "xspi-ker";
				clocks = <&rcc STM32_CLOCK(AHB5, 17)>,
					 <&rcc STM32_SRC_HCLK5 XSPI3_SEL(0)>;
				#address-cells = <1>;
				#size-cells = <0>;
				status = "disabled";
			};

			usbotg_hs1: otghs@8040000 {
				compatible = "st,stm32n6-otghs", "st,stm32-otghs";
				reg = <0x8040000 0x2000>;
				interrupts = <177 0>;
				interrupt-names = "otghs";
				num-bidir-endpoints = <9>;
				ram-size = <4096>;
				maximum-speed = "high-speed";
				clocks = <&rcc STM32_CLOCK(AHB5, 26)>,
					 <&rcc STM32_SRC_HSE OTGPHY1CKREF_SEL(1)>;
				phys = <&usbphyc1>;
				status = "disabled";
			};

			usbotg_hs2: otghs@8080000 {
				compatible = "st,stm32n6-otghs", "st,stm32-otghs";
				reg = <0x8080000 0x2000>;
				interrupts = <178 0>;
				interrupt-names = "otghs";
				num-bidir-endpoints = <9>;
				ram-size = <4096>;
				maximum-speed = "high-speed";
				clocks = <&rcc STM32_CLOCK(AHB5, 29)>,
					 <&rcc STM32_SRC_HSE OTGPHY2CKREF_SEL(1)>;
				phys = <&usbphyc2>;
				status = "disabled";
			};

			usbphyc1: usbphyc@803fc00 {
				compatible = "st,stm32-usbphyc";
				reg = <0x803fc00 0x400>;
				clocks = <&rcc STM32_CLOCK(AHB5, 27)>;
				#phy-cells = <0>;
			};

			usbphyc2: usbphyc@80c0000 {
				compatible = "st,stm32-usbphyc";
				reg = <0x80c0000 0x400>;
				clocks = <&rcc STM32_CLOCK(AHB5, 28)>;
				#phy-cells = <0>;
			};

			ltdc: ltdc@8001000 {
				compatible = "st,stm32-ltdc";
				reg = <0x8001000 0x1000>;
				interrupts = <193 0>, <194 0>;
				interrupt-names = "ltdc", "ltdc_er";
				clocks = <&rcc STM32_CLOCK(APB5, 1)>,
					 <&rcc STM32_SRC_PCLK5 LTDC_SEL(0)>;
				resets = <&rctl STM32_RESET(APB5, 1)>;
				status = "disabled";
			};

			rng: rng@4020000 {
				compatible = "st,stm32-rng";
				reg = <0x4020000 0x400>;
				interrupts = <40 0>;
				clocks = <&rcc STM32_CLOCK(AHB3, 0)>;
				nist-config = <0xf00d00>;
				health-test-config = <0xaac7>;
				status = "disabled";
			};

			sai1_a: sai1@2005804 {
				compatible = "st,stm32-sai";
				#address-cells = <1>;
				#size-cells = <0>;
				reg = <0x2005804 0x20>;
				clocks = <&rcc STM32_CLOCK(APB2, 21)>;
				dmas = <&gpdma1 1 91 (STM32_DMA_MODE_NORMAL |
						      STM32_DMA_PRIORITY_HIGH |
						      STM32_DMA_16BITS)>;
				status = "disabled";
			};

			sai1_b: sai1@2005824 {
				compatible = "st,stm32-sai";
				#address-cells = <1>;
				#size-cells = <0>;
				reg = <0x2005824 0x20>;
				clocks = <&rcc STM32_CLOCK(APB2, 21)>;
				dmas = <&gpdma1 0 92 (STM32_DMA_MODE_NORMAL |
						      STM32_DMA_PRIORITY_HIGH |
						      STM32_DMA_16BITS)>;
				status = "disabled";
			};

			sai2_a: sai2@2005c04 {
				compatible = "st,stm32-sai";
				#address-cells = <1>;
				#size-cells = <0>;
				reg = <0x2005c04 0x20>;
				clocks = <&rcc STM32_CLOCK(APB2, 22)>;
				dmas = <&gpdma1 3 93 (STM32_DMA_MODE_NORMAL |
						      STM32_DMA_PRIORITY_HIGH |
						      STM32_DMA_16BITS)>;
				status = "disabled";
			};

			sai2_b: sai2@2005c24 {
				compatible = "st,stm32-sai";
				#address-cells = <1>;
				#size-cells = <0>;
				reg = <0x2005c24 0x20>;
				clocks = <&rcc STM32_CLOCK(APB2, 22)>;
				dmas = <&gpdma1 2 94 (STM32_DMA_MODE_NORMAL |
						      STM32_DMA_PRIORITY_HIGH |
						      STM32_DMA_16BITS)>;
				status = "disabled";
			};

			npu: npu@80e0000 {
				compatible = "st,stm32-npu";
				reg = <0x80e0000 DT_SIZE_K(128)>;
				clocks = <&rcc STM32_CLOCK(AHB5, 31)>;
				resets = <&rctl STM32_RESET(AHB5, 31)>;
				status = "disabled";
			};

			npu_cache: cache-controller@80dfc00 {
				compatible = "st,stm32-npu-cache";
				reg = <0x80dfc00 DT_SIZE_K(1)>;
				clocks = <&rcc STM32_CLOCK(AHB5, 30)>;
				resets = <&rctl STM32_RESET(AHB5, 30)>;
				status = "okay";
			};

			venc: venc@8005000 {
				compatible = "st,stm32-venc";
				reg = <0x8005000 0x1000>;
				interrupts = <62 0>;
				clocks = <&rcc STM32_CLOCK(APB5, 5)>;
				resets = <&rctl STM32_RESET(APB5, 5)>;
				status = "disabled";
			};

			jpeg: codec@8023000 {
				compatible = "st,stm32-jpeg";
				reg = <0x8023000 0x1000>;
				interrupts = <61 0>;
				clocks = <&rcc STM32_CLOCK(AHB5, 3)>;
				resets = <&rctl STM32_RESET(AHB5, 3)>;
				status = "disabled";
			};

			iwdg: watchdog@6004800 {
				compatible = "st,stm32-watchdog";
				reg = <0x6004800 0x400>;
				interrupts = <18 0>;
				status = "disabled";
			};

			wwdg: watchdog@2c00 {
				compatible = "st,stm32-window-watchdog";
				reg = <0x2c00 0x400>;
				clocks = <&rcc STM32_CLOCK(APB1, 11)>;
				interrupts = <19 0>;
				status = "disabled";
			};

			crc: crc@6024c00 {
				compatible = "st,stm32-crc";
				reg = <0x6024c00 0x400>;
				clocks = <&rcc STM32_CLOCK(AHB4, 19)>;
				resets = <&rctl STM32_RESET(AHB4, 19)>;
				status = "disabled";
			};
		};
	};

	iocell: iocell {
		compatible = "st,stm32-iocell";
		status = "disabled";

		/* If iocell is enabled,
		 * the bsec node needs to be enabled as well
		 */
		nvmem-cells = <&otp124_hconf1>;
		nvmem-cell-names = "safeguard";

		vddio {
			domain = <STM32_DT_IOCELL_VDD>;
		};

		vddio2 {
			domain = <STM32_DT_IOCELL_VDDIO2>;
		};

		vddio3 {
			domain = <STM32_DT_IOCELL_VDDIO3>;
		};

		vddio4 {
			domain = <STM32_DT_IOCELL_VDDIO4>;
		};

		vddio5 {
			domain = <STM32_DT_IOCELL_VDDIO5>;
		};
	};
};

&nvic {
	arm,num-irq-priority-bits = <4>;
};
